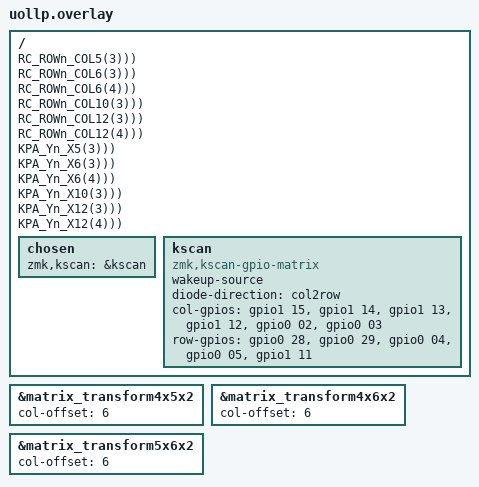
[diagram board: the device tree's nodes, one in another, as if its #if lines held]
#include <physical_layouts.dtsi>
#include <dt-bindings/zmk/matrix_transform.h>

#define RC_ROWn_COLi5(n, i) RC(n, (0 + i)) RC(n, (1 + i)) RC(n, (2 + i)) RC(n, (3 + i)) RC(n, (4 + i))
#define RC_ROWn_COL5(n) RC_ROWn_COLi5(n, 1)
#define RC_ROWn_COL6(n) RC_ROWn_COLi5(n, 0) RC(n, 5)
#define RC_ROWn_COL10(n) RC_ROWn_COLi5(n, 1) RC_ROWn_COLi5(n, 7)
#define RC_ROWn_COL12(n) RC_ROWn_COLi5(n, 0) RC(n, 5) RC_ROWn_COLi5(n, 6) RC(n, 11)

#define KEY_PHYSICAL_SIZE_X 100
#define KEY_PHYSICAL_SIZE_Y 100
#define KPA(x, y) <&key_physical_attrs KEY_PHYSICAL_SIZE_X KEY_PHYSICAL_SIZE_Y (x * KEY_PHYSICAL_SIZE_X) (y * KEY_PHYSICAL_SIZE_Y) 0 0 0>
#define KPA_Yn_Xi5(i, n) KPA((0 + i), n), KPA((1 + i), n), KPA((2 + i), n), KPA((3 + i), n), KPA((4 + i), n)
#define KPA_Yn_X5(n) KPA_Yn_Xi5(1, n)
#define KPA_Yn_X6(n) KPA_Yn_Xi5(0, n), KPA(5, n)
#define KPA_Yn_X10(n) KPA_Yn_Xi5(1, n), KPA_Yn_Xi5(7, n)
#define KPA_Yn_X12(n) KPA_Yn_Xi5(0, n), KPA(5, n), KPA_Yn_Xi5(7, n), KPA(12, n)

#define MT(r, c, m) compatible = "zmk,matrix-transform"; \
    rows = <r>; columns = <c>; map = <m>;
#define PL(n, k, t, ...) compatible = "zmk,physical-layout"; \
    display-name = n; kscan = <k>; transform = <t>; keys = __VA_ARGS__;

#define NODE_LABEL(n, b) n: n { b }

/ {

    chosen {
        
        zmk,kscan = &kscan;
    };

    kscan: kscan {

        compatible = "zmk,kscan-gpio-matrix";
        wakeup-source;
        diode-direction = "col2row";
        col-gpios
            = <&gpio1 15 GPIO_ACTIVE_HIGH>
            , <&gpio1 14 GPIO_ACTIVE_HIGH>
            , <&gpio1 13 GPIO_ACTIVE_HIGH>
            , <&gpio1 12 GPIO_ACTIVE_HIGH>
            , <&gpio0 02 GPIO_ACTIVE_HIGH>
            , <&gpio0 03 GPIO_ACTIVE_HIGH>
        ;
        row-gpios
            = <&gpio0 28 (GPIO_ACTIVE_HIGH | GPIO_PULL_DOWN)>
            , <&gpio0 29 (GPIO_ACTIVE_HIGH | GPIO_PULL_DOWN)>
            , <&gpio0 04 (GPIO_ACTIVE_HIGH | GPIO_PULL_DOWN)>
            , <&gpio0 05 (GPIO_ACTIVE_HIGH | GPIO_PULL_DOWN)>
            , <&gpio1 11 (GPIO_ACTIVE_HIGH | GPIO_PULL_DOWN)>
        ;
    };

    NODE_LABEL(matrix_transform4x5x1, MT(4, 5, RC_ROWn_COL5(0) RC_ROWn_COL5(1) RC_ROWn_COL5(2) RC_ROWn_COL5(3)));
    NODE_LABEL(matrix_transform4x6x1, MT(4, 6, RC_ROWn_COL6(0) RC_ROWn_COL6(1) RC_ROWn_COL6(2) RC_ROWn_COL6(3)));
    NODE_LABEL(matrix_transform5x6x1, MT(5, 6, RC_ROWn_COL6(0) RC_ROWn_COL6(1) RC_ROWn_COL6(2) RC_ROWn_COL6(3) RC_ROWn_COL6(4)));

    NODE_LABEL(matrix_transform4x5x2, MT(4, 10, RC_ROWn_COL10(0) RC_ROWn_COL10(1) RC_ROWn_COL10(2) RC_ROWn_COL10(3)));
    NODE_LABEL(matrix_transform4x6x2, MT(4, 12, RC_ROWn_COL12(0) RC_ROWn_COL12(1) RC_ROWn_COL12(2) RC_ROWn_COL12(3)));
    NODE_LABEL(matrix_transform5x6x2, MT(5, 12, RC_ROWn_COL12(0) RC_ROWn_COL12(1) RC_ROWn_COL12(2) RC_ROWn_COL12(3) RC_ROWn_COL12(4)));

    NODE_LABEL(layout4x5x1, PL("4x5x1", &kscan, &matrix_transform4x5x1, KPA_Yn_X5(0), KPA_Yn_X5(1), KPA_Yn_X5(2), KPA_Yn_X5(3)));
    NODE_LABEL(layout4x6x1, PL("4x6x1", &kscan, &matrix_transform4x6x1, KPA_Yn_X6(0), KPA_Yn_X6(1), KPA_Yn_X6(2), KPA_Yn_X6(3)));
    NODE_LABEL(layout5x6x1, PL("5x6x1", &kscan, &matrix_transform5x6x1, KPA_Yn_X6(0), KPA_Yn_X6(1), KPA_Yn_X6(2), KPA_Yn_X6(3), KPA_Yn_X6(4)));

    NODE_LABEL(layout4x5x2, PL("4x5x2", &kscan, &matrix_transform4x5x2, KPA_Yn_X10(0), KPA_Yn_X10(1), KPA_Yn_X10(2), KPA_Yn_X10(3)));
    NODE_LABEL(layout4x6x2, PL("4x6x2", &kscan, &matrix_transform4x6x2, KPA_Yn_X12(0), KPA_Yn_X12(1), KPA_Yn_X12(2), KPA_Yn_X12(3)));
    NODE_LABEL(layout5x6x2, PL("5x6x2", &kscan, &matrix_transform5x6x2, KPA_Yn_X12(0), KPA_Yn_X12(1), KPA_Yn_X12(2), KPA_Yn_X12(3), KPA_Yn_X12(4)));
};

#if defined(ZMK_SPLIT) && !defined(ZMK_SPLIT_ROLE_CENTRAL)

&matrix_transform4x5x2 { col-offset = <6>; };
&matrix_transform4x6x2 { col-offset = <6>; };
&matrix_transform5x6x2 { col-offset = <6>; };

#endif

